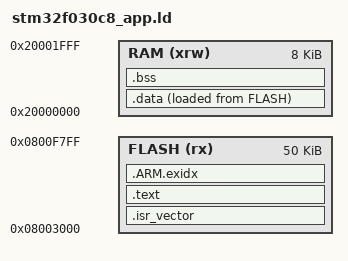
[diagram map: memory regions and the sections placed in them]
MEMORY
{
  FLASH (rx) : ORIGIN = 0x08003000, LENGTH = 50K
  RAM (xrw)  : ORIGIN = 0x20000000, LENGTH = 8K
}
_estack = ORIGIN(RAM) + LENGTH(RAM);
SECTIONS
{
  .isr_vector : { KEEP(*(.isr_vector)) } > FLASH
  .text : { *(.text*) *(.rodata*) KEEP(*(.init)) KEEP(*(.fini)) } > FLASH
  .ARM.exidx : { *(.ARM.exidx*) } > FLASH
  _sidata = LOADADDR(.data);
  .data : { _sdata = .; *(.data*) _edata = .; } > RAM AT> FLASH
  .bss : { _sbss = .; *(.bss*) *(COMMON) _ebss = .; } > RAM
  . = ALIGN(8); _end = .;
}
